# nrf5002 register map
Vendor: Nordic Semiconductor; Series: nRF50; File version: 1
CPU: CM0 r0p4, little endian, no MPU, no FPU, 2 interrupt priority bits, 32 interrupts
Registers are 32-bit, read-write, reset 0x0 unless marked. A register's access mark holds for its fields unless they carry their own. Offsets are from the block's base; [hi:lo] are bit positions; lines under a group give offsets from that group; {n}, {i} and the like mark numbered series; 'fields as' and 'values as' point back to an identical list.

## UICR — User Information Configuration Registers
Base 0x10001000
0x00 APPROTECT — Access port protection
  [31:0] PALL — Blocks debugger read/write access to all CPU registers and memory mapped addresses except for the control access port registers. Between reset and automatic readout, the system is protected Using any value except Unprotected will lead to the protection being enabled.
    0xFFFFFFFF=Unprotected; 0=Protected
0x24 TINSTANCE reset 0xFFFFFFFF — SW-DP Target instance
  [31:28] TINSTANCE — TINSTANCE bits are negated and used in the SW-DP DLPIDR.TINSTANCE field. E.g. 0xF in this field is translated to 0x0 in DLPIDR.TINSTANCE field.
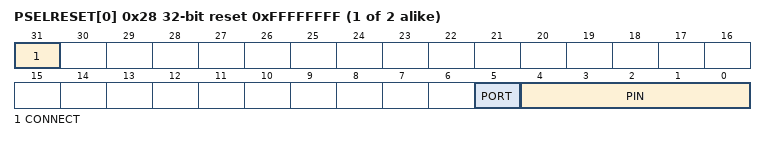
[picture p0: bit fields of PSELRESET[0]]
{0x28+4i} PSELRESET[{i}] (i=0..1) reset 0xFFFFFFFF — Description collection: Mapping of the nRESET function (see POWER chapter for details)
  [31] CONNECT — Connection
    1=Disconnected; 0=Connected
  [5] PORT — Port number onto which nRESET is exposed
  [4:0] PIN — GPIO pin number onto which nRESET is exposed

## PAMLI — Peripheral AHB Multi-Layer Interface
Base 0x40020000
0xE00 RAMPRI group — RAM configurable priority configuration structure
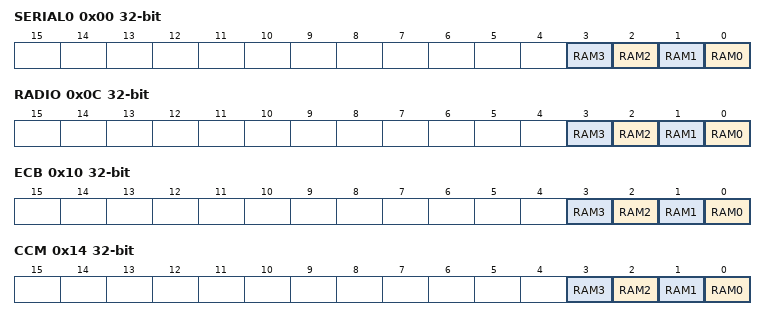
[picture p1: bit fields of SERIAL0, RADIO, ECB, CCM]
  0x00 SERIAL0 — AHB bus master priority register for SPIM0, SPIS0, TWIM0, TWIS0 and UARTE0
    [all] fields
      0=Pri0 (Priority 0); 1=Pri1 (Priority 1)
    [n] RAM{n} (n=0..3) — Priority register for RAM AHB slave {n}
  0x0C RADIO — AHB bus master priority register for RADIO
    fields as RAMPRI.SERIAL0
  0x10 ECB — AHB bus master priority register for ECB
    fields as RAMPRI.SERIAL0
  0x14 CCM — AHB bus master priority register for CCM
    fields as RAMPRI.SERIAL0
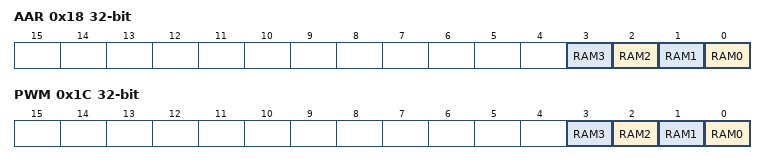
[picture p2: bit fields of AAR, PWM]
  0x18 AAR — AHB bus master priority register for AAR
    fields as RAMPRI.SERIAL0
  0x1C PWM — AHB bus master priority register for PWM0
    fields as RAMPRI.SERIAL0

## VMC — Volatile Memory controller
Base 0x40022000
{0x600+0x10*i} RAM[{i}] (i=0..1) group — Unspecified
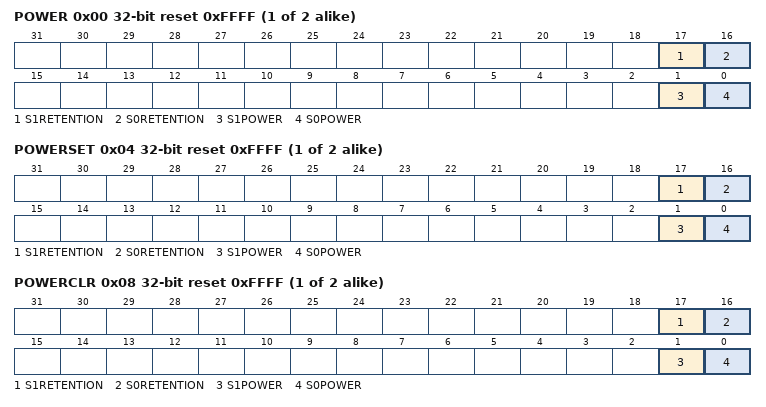
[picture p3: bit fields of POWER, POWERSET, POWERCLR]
  0x00 POWER reset 0xFFFF — Description cluster: RAM[n] power control register
    [all] fields
      0=Off; 1=On
    [17] S1RETENTION — Keep retention on RAM section S1 of RAM[n] when RAM section is switched off
    [16] S0RETENTION — Keep retention on RAM section S0 of RAM[n] when RAM section is switched off
    [1] S1POWER — Keep RAM section S1 of RAM[n] on or off in System ON mode
    [0] S0POWER — Keep RAM section S0 of RAM[n] on or off in System ON mode
  0x04 POWERSET reset 0xFFFF — Description cluster: RAM[n] power control set register
    [all] fields
      1=On
    [17] S1RETENTION — Keep retention on RAM section S1 of RAM[n] when RAM section is switched off
    [16] S0RETENTION — Keep retention on RAM section S0 of RAM[n] when RAM section is switched off
    [1] S1POWER — Keep RAM section S1 of RAM[n] on or off in System ON mode
    [0] S0POWER — Keep RAM section S0 of RAM[n] on or off in System ON mode
  0x08 POWERCLR reset 0xFFFF — Description cluster: RAM[n] power control clear register
    [all] fields
      1=Off
    [17] S1RETENTION — Keep retention on RAM section S1 of RAM[n] when RAM section is switched off
    [16] S0RETENTION — Keep retention on RAM section S0 of RAM[n] when RAM section is switched off
    [1] S1POWER — Keep RAM section S1 of RAM[n] on or off in System ON mode
    [0] S0POWER — Keep RAM section S0 of RAM[n] on or off in System ON mode

## BPROT — Block Protect
Base 0x40023000
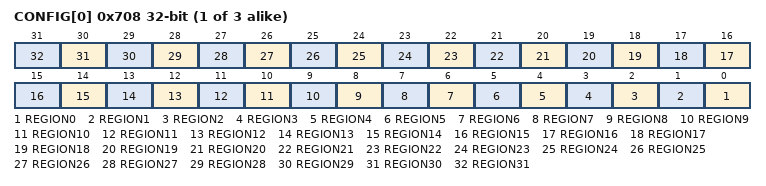
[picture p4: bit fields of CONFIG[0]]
{0x708+4i} CONFIG[{i}] (i=0..2) — Description collection: Block protect configuration register n.
  [all] fields
    0=Disabled (Disable protection.); 1=Enabled (Enable protection.)
  [n] REGION{n} (n=0..31) — Enable protection for region {n}. Writing '0' has no effect.
